# MKV56F20 register map
Vendor: Freescale Semiconductor, Inc.; Series: Kinetis_V; File version: 1.6
CPU: CM7 r0p1, little endian, no MPU, FPU, VTOR, 4 interrupt priority bits
Registers are 32-bit, read-write, reset 0x0 unless marked. A register's access mark holds for its fields unless they carry their own. Offsets are from the block's base; [hi:lo] are bit positions; {n}, {i} and the like mark numbered series; 'fields as' and 'values as' point back to an identical list.

## SIM — System Integration Module
Base 0x40047000; register names take the prefix SIM_
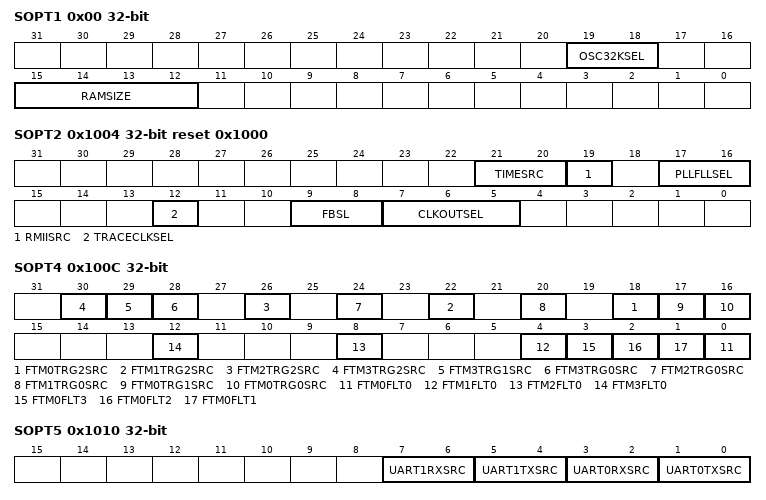
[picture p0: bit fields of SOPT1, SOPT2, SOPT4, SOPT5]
0x00 SOPT1 (reset mask 0xFFFF0FFF) — System Options Register 1
  [19:18] OSC32KSEL — 32K oscillator clock select
    0=System oscillator (OSC32KCLK); 3=LPO 1 kHz
  [15:12] RAMSIZE ro
    9=128 KB; 11=256 KB
0x1004 SOPT2 reset 0x1000 — System Options Register 2
  [21:20] TIMESRC — IEEE 1588 timestamp clock source select
    0=Core/system clock; 1=MCGFLLCLK , or MCGPLLCLK as selected by SOPT2[PLLFLLSEL]; 2=OSCERCLK clock; 3=External bypass clock (ENET_1588_CLKIN)
  [19] RMIISRC — RMII clock source select
    0=EXTAL clock; 1=External bypass clock (ENET_1588_CLKIN)
  [17:16] PLLFLLSEL — PLL/FLL clock select
    0=MCGFLLCLK clock; 1=MCGPLLCLK clock
  [12] TRACECLKSEL — Debug trace clock select
    0=MCGOUTCLK; 1=Core/system clock
  [9:8] FBSL — FlexBus security level
    0=All off-chip accesses (instruction and data) via the FlexBus are disallowed; 1=All off-chip accesses (instruction and data) via the FlexBus are disallowed; 2=Off-chip instruction accesses are disallowed. Data accesses are allowed.; 3=Off-chip instruction accesses and data accesses are allowed
  [7:5] CLKOUTSEL — CLKOUT select
    0=FlexBus CLKOUT; 2=Flash clock; 3=LPO clock (1 kHz); 4=MCGIRCLK; 5=OSCERCLK_UNDIV; 6=OSCERCLK
0x100C SOPT4 — System Options Register 4
  [4n+18] FTM{n}TRG2SRC (n=0..3) — FlexTimer {n} Hardware Trigger 2 Source Select
    0=FTM{n}_FLT0 pin drives FTM{n} hardware trigger 2; 1=XBARA output {n+34} drives FTM{n} hardware trigger 2
  [29] FTM3TRG1SRC — FlexTimer 3 Hardware Trigger 1 Source Select
    0=PDB1 channel 1 output trigger drives FTM3 hardware trigger 1; 1=FTM1 channel match drives FTM3 hardware trigger 1
  [28] FTM3TRG0SRC — FlexTimer 3 Hardware Trigger 0 Source Select
    0=CMP0 output drives FTM3 hardware trigger 0; 1=FTM1 channel match drives FTM3 hardware trigger 0
  [24] FTM2TRG0SRC — FlexTimer 2 Hardware Trigger 0 Source Select
    0=CMP0 output drives FTM2 hardware trigger 0; 1=FTM0 channel match drives FTM2 hardware trigger 0
  [20] FTM1TRG0SRC — FlexTimer 1 Hardware Trigger 0 Source Select
    0=CMP0 output drives FTM1 hardware trigger 0; 1=FTM0 channel match drives FTM1 hardware trigger 0
  [17] FTM0TRG1SRC — FlexTimer 0 Hardware Trigger 1 Source Select
    0=PDB0 channel 1 output trigger drives FTM0 hardware trigger 1; 1=FTM1 channel match drives FTM0 hardware trigger 1
  [16] FTM0TRG0SRC — FlexTimer 0 Hardware Trigger 0 Source Select
    0=CMP0 output drives FTM0 hardware trigger 0; 1=FTM1 channel match drives FTM0 hardware trigger 0
  [4n] FTM{n}FLT0 (n=0..3) — FTM{n} Fault 0 Select
    0=FTM{n}_FLT0 pin; 1=CMP0 out
  [3] FTM0FLT3 — Selects the source of FTM0 fault 3
    0=FTM0_FLT3 pin; 1=XBARA output 49
  [2] FTM0FLT2 — FTM0 Fault 2 Select
    0=FTM0_FLT2 pin; 1=CMP2 out
  [1] FTM0FLT1 — FTM0 Fault 1 Select
    0=FTM0_FLT1 pin; 1=CMP1 out
0x1010 SOPT5 — System Options Register 5
  [7:6] UART1RXSRC — UART 1 receive data source select
    0=UART1_RX pin; 1=CMP0; 2=CMP1
  [5:4] UART1TXSRC — UART 1 transmit data source select
    0=UART1_TX pin; 1=UART1_TX pin modulated with FTM1 channel 0 output; 2=UART1_TX pin modulated with FTM2 channel 0 output
  [3:2] UART0RXSRC — UART 0 receive data source select
    0=UART0_RX pin; 1=CMP0; 2=CMP1
  [1:0] UART0TXSRC — UART 0 transmit data source select
    0=UART0_TX pin; 1=UART0_TX pin modulated with FTM1 channel 0 output; 2=UART0_TX pin modulated with FTM2 channel 0 output
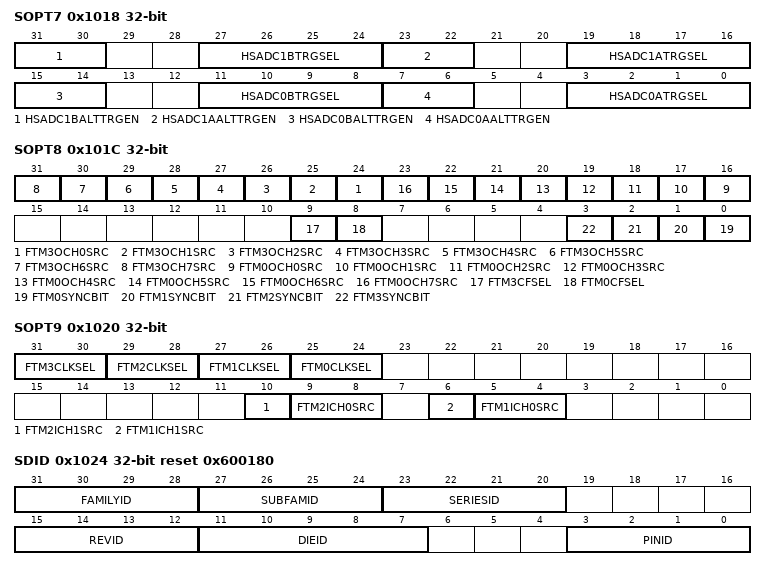
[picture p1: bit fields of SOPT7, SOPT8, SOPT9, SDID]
0x1018 SOPT7 — System Options Register 7
  [31:30] HSADC1BALTTRGEN — HSADC1B alternate trigger enable
    0=XBARA output 43; 1=PDB0 channel 1 trigger selected for HSADC1B
  [27:24] HSADC1BTRGSEL — HSADC1B trigger select
    0=PDB external trigger pin input (PDB0_EXTRG); 1=High speed comparator 0 output; 2=High speed comparator 1 output; 3=High speed comparator 2 output; {v}=PIT trigger {v-4} (v=4..7); {v}=FTM{v-8} trigger (v=8..11); 12=XBARA output 38; 14=Low-power timer trigger
  [23:22] HSADC1AALTTRGEN — HSADC1A alternate trigger enable
    0=XBARA output 42; 1=PDB1 channel 1 trigger selected for HSADC1A
  [19:16] HSADC1ATRGSEL — HSADC1A trigger select
    1=High speed comparator 0 output; 2=High speed comparator 1 output; 3=High speed comparator 2 output; {v}=PIT trigger {v-4} (v=4..7); {v}=FTM{v-8} trigger (v=8..11); 12=XBARA output 41; 14=Low-power timer trigger
  [15:14] HSADC0BALTTRGEN — HSADC0B alternate trigger enable
    0=XBARA output 13; 1=PDB1 channel0 trigger selected for HSADC0B
  [11:8] HSADC0BTRGSEL — HSADC0B trigger select
    values as HSADC1ATRGSEL
  [7:6] HSADC0AALTTRGEN — HSADC0A alternate trigger enable
    0=XBARA output 12; 1=PDB0 channel0 trigger selected for HSADC0A
  [3:0] HSADC0ATRGSEL — HSADC0A trigger select
    values as HSADC1BTRGSEL
0x101C SOPT8 — System Options Register 8
  [n+24] FTM3OCH{n}SRC (n=0..7) — FTM3 channel {n} output source
    0=FTM3_CH{n} pin is output of FTM3 channel {n} output; 1=FTM3_CH{n} pin is output of FTM3 channel {n} output modulated by carrier frequency clock, as per FTM3CFSEL
  [n+16] FTM0OCH{n}SRC (n=0..7) — FTM0 channel {n} output source
    0=FTM0_CH{n} pin is output of FTM0 channel {n} output; 1=FTM0_CH{n} pin is output of FTM0 channel {n} output, modulated by carrier frequency clock, as per FTM0CFSEL
  [9] FTM3CFSEL — Carrier frequency selection for FTM3 output channel
    0=FTM1 channel 1 output provides the carrier signal for FTM3 Timer Modulation mode; 1=LPTMR0 prescaler output provides the carrier signal for FTM3 Timer Modulation mode
  [8] FTM0CFSEL — Carrier frequency selection for FTM0 output channel
    0=FTM1 channel 1 output provides the carrier signal for FTM0 Timer Modulation mode; 1=LPTMR0 prescaler output provides the carrier signal for FTM0 Timer Modulation mode
  [n] FTM{n}SYNCBIT (n=0..3) — FTM{n} Hardware Trigger 0 Software Synchronization
    0=No effect; 1=Write 1 to assert the TRIG0 input to FTM{n}, software must clear this bit to allow other trigger sources to assert
0x1020 SOPT9 — System Options Register 9
  [2n+25:2n+24] FTM{n}CLKSEL (n=0..3) — FlexTimer {n} External Clock Pin Select
    0=FTM{n} external clock driven by FTM_CLK0 pin; 1=FTM{n} external clock driven by FTM_CLK1 pin; 2=FTM{n} external clock driven by FTM_CLK2 pin
  [10] FTM2ICH1SRC — FTM2 channel 1 input capture source select
    0=FTM2_CH1 signal; 1=Exclusive OR of FTM2_CH1, FTM2_CH0 and FTM1_CH1
  [9:8] FTM2ICH0SRC — FTM2 channel 0 input capture source select
    0=FTM2_CH0 signal; 1=CMP0 output; 2=CMP1 output
  [6] FTM1ICH1SRC — FTM1 channel 0 input capture source select
    0=FTM1_CH1 signal; 1=Exclusive OR of FTM1_CH1, FTM1_CH0, and XBARA output 42 (XBARA output 42 can also trigger HSADC1A sync0)
  [5:4] FTM1ICH0SRC — FTM1 channel 0 input capture source select
    0=FTM1_CH0 signal; 1=CMP0 output; 2=CMP1 output
0x1024 SDID ro reset 0x600180 (reset mask 0xFF0FF0) — System Device Identification Register
  [31:28] FAMILYID — Kinetis Family ID
    5=This is the KV5x series
  [27:24] SUBFAMID — Kinetis Sub-Family ID
    6=KVx6 Subfamily (eFlexPWM with FlexTimer and HSADC); 8=KVx8 Subfamily (eFlexPWM with FlexTimer, HSADC, and Ethernet)
  [23:20] SERIESID — Kinetis Series ID
    6=Kinetis V series
  [15:12] REVID — Device revision number
  [11:7] DIEID — Device die number
    3=KV5x
  [3:0] PINID — Pincount identification
    8=100-pin; 10=144-pin
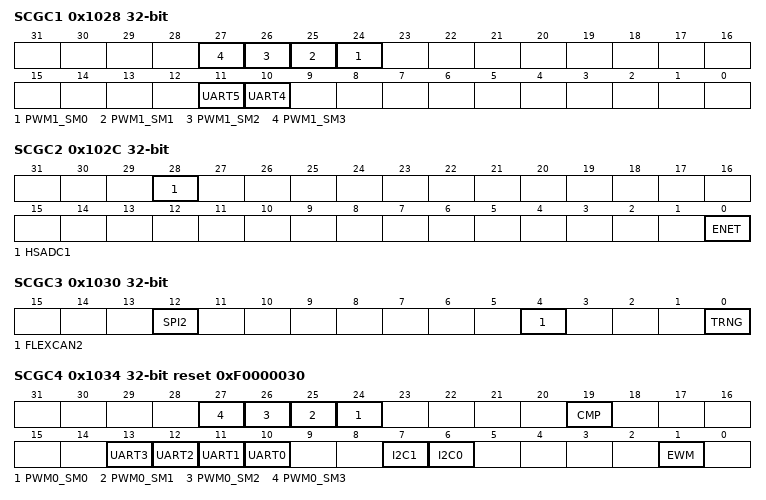
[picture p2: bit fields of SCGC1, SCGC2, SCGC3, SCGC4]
0x1028 SCGC1 — System Clock Gating Control Register 1
  [all] fields
    0=Clock disabled; 1=Clock enabled
  [n+24] PWM1_SM{n} (n=0..3) — PWM1 submodule {n} Clock Gate Control
  [11] UART5 — UART5 Clock Gate Control
  [10] UART4 — UART4 Clock Gate Control
0x102C SCGC2 — System Clock Gating Control Register 2
  [28] HSADC1 — HSADC1 Clock Gate Control
    0=Clock disabled; 1=Clock enabled
  [0] ENET — ENET Clock Gate Control
    0=Clock disabled; 1=Clock enabled
0x1030 SCGC3 — System Clock Gating Control Register 3
  [all] fields
    0=Clock disabled; 1=Clock enabled
  [12] SPI2 — SPI2 Clock Gate Control
  [4] FLEXCAN2 — FlexCAN2 Clock Gate Control
  [0] TRNG — TRNG Clock Gate Control
0x1034 SCGC4 reset 0xF0000030 — System Clock Gating Control Register 4
  [n+24] PWM0_SM{n} (n=0..3) — PWM0 submodule {n} Clock Gate Control
    0=Clock disabled; 1=Clock enabled
  [19] CMP — Comparators Clock Gate Control
    0=Clock disabled; 1=Clock enabled
  [n+10] UART{n} (n=0..3) — UART{n} Clock Gate Control
    0=Clock disabled; 1=Clock enabled
  [7] I2C1 — I2C1 Clock Gate Control
  [6] I2C0 — I2C0 Clock Gate Control
    0=Clock disabled; 1=Clock enabled
  [1] EWM — EWM Clock Gate Control
    0=Clock disabled; 1=Clock enabled
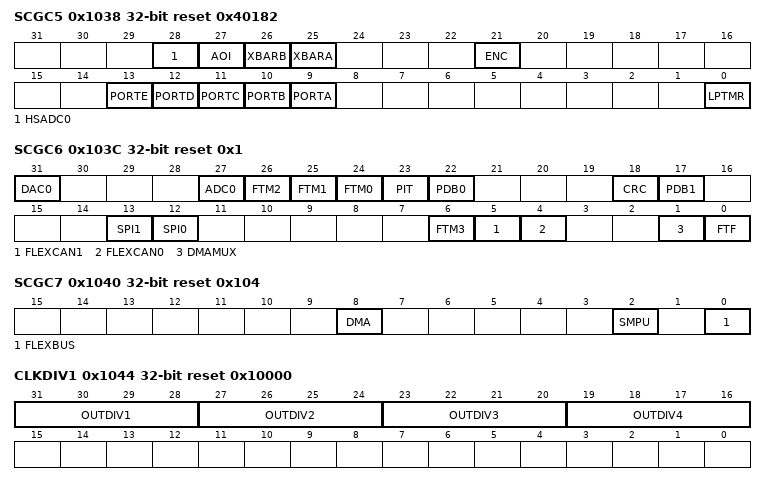
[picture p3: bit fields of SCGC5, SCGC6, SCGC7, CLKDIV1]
0x1038 SCGC5 reset 0x40182 — System Clock Gating Control Register 5
  [28] HSADC0 — HSADC0 Clock Gate Control
    0=Clock disabled; 1=Clock enabled
  [27] AOI — AOI Clock Gate Control
    0=Clock disabled; 1=Clock enabled
  [26] XBARB — XBARB Clock Gate Control
    0=Clock disabled; 1=Clock enabled
  [25] XBARA — XBARA Clock Gate Control
    0=Clock disabled; 1=Clock enabled
  [21] ENC — This bit controls the clock gate to the ENC module.
    0=Clock disabled; 1=Clock enabled
  [13] PORTE — Port E Clock Gate Control
    0=Clock disabled; 1=Clock enabled
  [12] PORTD — Port D Clock Gate Control
    0=Clock disabled; 1=Clock enabled
  [11] PORTC — Port C Clock Gate Control
    0=Clock disabled; 1=Clock enabled
  [10] PORTB — Port B Clock Gate Control
    0=Clock disabled; 1=Clock enabled
  [9] PORTA — Port A Clock Gate Control
    0=Clock disabled; 1=Clock enabled
  [0] LPTMR — Low Power Timer Access Control
    0=Access disabled; 1=Access enabled
0x103C SCGC6 reset 0x1 — System Clock Gating Control Register 6
  [all] fields
    0=Clock disabled; 1=Clock enabled
  [31] DAC0 — DAC0 Clock Gate Control
  [27] ADC0 — ADC0 Clock Gate Control
  [26] FTM2 — FTM2 Clock Gate Control
  [25] FTM1 — FTM1 Clock Gate Control
  [24] FTM0 — FTM0 Clock Gate Control
  [23] PIT — PIT Clock Gate Control
  [22] PDB0 — PDB0 Clock Gate Control
  [18] CRC — CRC Clock Gate Control
  [17] PDB1 — PDB1 Clock Gate Control
  [13] SPI1 — SPI1 Clock Gate Control
  [12] SPI0 — SPI0 Clock Gate Control
  [6] FTM3 — FTM3 Clock Gate Control
  [5] FLEXCAN1 — FlexCAN1 Clock Gate Control
  [4] FLEXCAN0 — FlexCAN0 Clock Gate Control
  [1] DMAMUX — DMA Mux Clock Gate Control
  [0] FTF — Flash Memory Clock Gate Control
0x1040 SCGC7 reset 0x104 — System Clock Gating Control Register 7
  [all] fields
    0=Clock disabled; 1=Clock enabled
  [8] DMA — DMA Clock Gate Control
  [2] SMPU — SMPU Clock Gate Control
  [0] FLEXBUS — FlexBus Clock Gate Control
0x1044 CLKDIV1 reset 0x10000 — System Clock Divider Register 1
  [all] fields
    {v}=Divide-by-{v+1} (v=0..15)
  [35-4n:32-4n] OUTDIV{n} (n=1..4) — Clock {n} output divider value
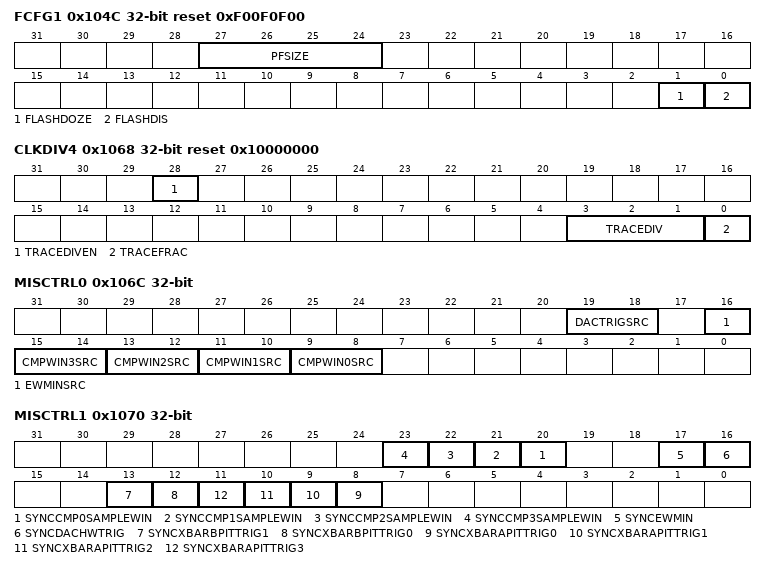
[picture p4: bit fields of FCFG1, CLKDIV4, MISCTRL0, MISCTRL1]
0x104C FCFG1 reset 0xF00F0F00 — Flash Configuration Register 1
  [27:24] PFSIZE ro — Program flash size
    11=512 KB of program flash memory; 13=1024 KB of program flash memory
  [1] FLASHDOZE
    0=Flash remains enabled during Wait mode; 1=Flash is disabled for the duration of Wait mode
  [0] FLASHDIS — Flash Disable
    0=Flash is enabled; 1=Flash is disabled
0x1050 FCFG2 ro reset 0x800000 — Flash Configuration Register 2
  [30:24] MAXADDR0 — Max address block 0
0x1054 UIDH ro reset not defined — Unique Identification Register High
  [31:0] UID — Unique Identification
0x1058 UIDMH ro reset not defined — Unique Identification Register Mid-High
  [31:0] UID — Unique Identification
0x105C UIDML ro reset not defined — Unique Identification Register Mid Low
  [31:0] UID — Unique Identification
0x1060 UIDL ro reset not defined — Unique Identification Register Low
  [31:0] UID — Unique Identification
0x1068 CLKDIV4 reset 0x10000000 — System Clock Divider Register 4
  [28] TRACEDIVEN — Debug Trace Divider Control
    0=Debug trace divider disabled; 1=Debug trace divider enabled
  [3:1] TRACEDIV — Trace clock divider divisor
  [0] TRACEFRAC — Trace clock divider fraction
0x106C MISCTRL0 — Miscellaneous Control Register 0
  [19:18] DACTRIGSRC — DAC0 Hardware Trigger Input Source
    0=XBARA output 15; 1=DAC0 can be triggered by both PDB0 interval trigger 0 and PDB1 interval trigger 0; 2=PDB0 interval trigger 0; 3=PDB1 interval trigger 0
  [16] EWMINSRC — EWM_IN Source
    0=XBARA output 58; 1=EWM_IN pin
  [2n+9:2n+8] CMPWIN{n}SRC (n=0..3) — CMP Sample/Window Input {n} Source
    0=XBARA output {n+16}; 1=CMP{n} Sample/Window input is driven by both PDB0 and PDB1 pluse-out channel {n}; 2=PDB0 pluse-out channel {n}; 3=PDB1 pluse-out channel {n}
0x1070 MISCTRL1 — Miscellaneous Control Register 1
  [all] fields
    0=Disable, bypass synchronizer; 1=Enable
  [n+20] SYNCCMP{n}SAMPLEWIN (n=0..3) — Synchronize XBARA's output for CMP{n}'s Sample/Window Input with flash/slow clock
  [17] SYNCEWMIN — Synchronize XBARA's output for EWM's ewm_in with flash/slow clock
  [16] SYNCDACHWTRIG — Synchronize XBARA's output for DAC Hardware Trigger with flash/slow clock
  [13] SYNCXBARBPITTRIG1 — Synchronize XBARB's Input PIT Trigger 1 with fast clock
  [12] SYNCXBARBPITTRIG0 — Synchronize XBARB's Input PIT Trigger 0 with fast clock
  [n+8] SYNCXBARAPITTRIG{n} (n=0..3) — Synchronize XBARA's Input PIT Trigger {n} with fast clock
0x1100 WDOGC — WDOG Control Register
  [1] WDOGCLKS — WDOG Clock Select
    0=1 kHz LPO clock is source to WDOG; 1=MCGIRCLK is source to WDOG
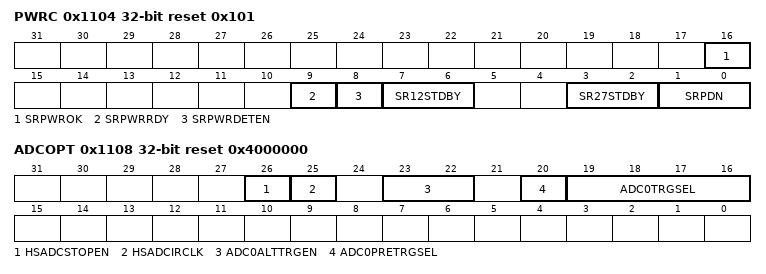
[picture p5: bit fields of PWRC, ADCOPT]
0x1104 PWRC reset 0x101 — Power Control Register
  [16] SRPWROK ro — Nanoedge PMC Status
    0=Power supply for nanoedge isn't ready; 1=Power supply for nanoedge is OK
  [9] SRPWRRDY — Nanoedge PMC POWER Ready
    0=Not ready; 1=Assert PMC power output ready
  [8] SRPWRDETEN — Nanoedge PMC POWER Dectect Enable
    0=Disable; 1=Enable
  [7:6] SR12STDBY — Nanoedge Regulator 1.2 V Supply Standby Control
    0=Nanoedge regulator 1.2 V supply placed in normal mode; 1=Nanoedge regulator 1.2 V supply placed in standby mode; 2=Nanoedge regulator 1.2 V supply placed in normal mode and SR12STDBY is write protected until chip reset; 3=Nanoedge regulator 1.2 V supply placed in standby mode and SR12STDBY is write protected until chip reset
  [3:2] SR27STDBY — Nanoedge Regulator 2.7 V Supply Standby Control
    0=Nanoedge regulator 2.7 V placed in normal mode; 1=Nanoedge regulator 2.7 V placed in standby mode; 2=Nanoedge regulator 2.7 V supply placed in normal mode and SR27STDBY is write protected until chip reset; 3=Nanoedge regulator 2.7 V supply placed in standby mode and SR27STDBY is write protected until chip reset
  [1:0] SRPDN — Nanoedge Regulator 2.7V and 1.2V Supply Powerdown Control
    0=Nanoedge regulator placed in normal mode; 1=Nanoedge regulator placed in powerdown mode; 2=Nanoedge regulator placed in normal mode and SRPDN is write protected until chip reset; 3=Nanoedge regulator placed in powerdown mode and SRPDN is write protected until chip reset
0x1108 ADCOPT reset 0x4000000 — ADC Additional Option Register
  [26] HSADCSTOPEN — Enable HSADCs in STOP mode
    0=HSADCs stopsin system STOP modes; 1=HSADCs can be enabled in system STOP modes
  [25] HSADCIRCLK ro — HSADC Clock Status
    0=HSADC clock is Core/System clock; 1=HSADC clock is MCGIRCLK
  [23:22] ADC0ALTTRGEN — ADC0 alternate trigger enable
    0=XBARA output 39; 1=PDB0 channel1 trigger selected for ADC0; 2=PDB1 channel0 trigger selected for ADC0; 3=Alternate trigger selected for ADC0 as defined by ADC0TRGSEL
  [20] ADC0PRETRGSEL — ADC0 pretrigger select
    0=Pre-trigger A; 1=Pre-trigger B
  [19:16] ADC0TRGSEL — ADC0 trigger select
    0=PDB0 external trigger pin input (PDB0_EXTRG); 1=High speed comparator 0 output; 2=High speed comparator 1 output; 3=High speed comparator 2 output; {v}=PIT trigger {v-4} (v=4..7); {v}=FTM{v-8} trigger (v=8..11); 12=XBARA output 38; 14=Low-power timer (LPTMR) trigger
